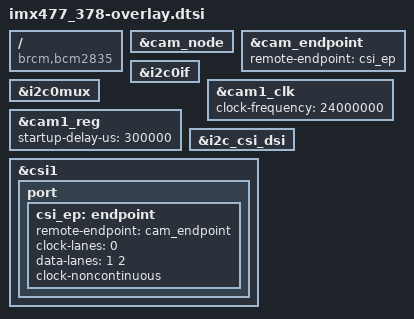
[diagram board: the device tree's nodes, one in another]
// SPDX-License-Identifier: GPL-2.0-only
// Definitions for IMX477 camera module on VC I2C bus

/{
	compatible = "brcm,bcm2835";

	fragment@0 {
		target = <&i2c0if>;
		__overlay__ {
			status = "okay";
		};
	};

	clk_frag: fragment@1 {
		target = <&cam1_clk>;
		cam_clk: __overlay__ {
			clock-frequency = <24000000>;
			status = "okay";
		};
	};

	fragment@2 {
		target = <&i2c0mux>;
		__overlay__ {
			status = "okay";
		};
	};

	reg_frag: fragment@3 {
		target = <&cam1_reg>;
		cam_reg: __overlay__ {
			startup-delay-us = <300000>;
		};
	};

	reg_alwayson_frag: fragment@99 {
		target = <&cam1_reg>;
		__dormant__ {
			regulator-always-on;
		};
	};

	i2c_frag: fragment@100 {
		target = <&i2c_csi_dsi>;
		__overlay__ {
			#address-cells = <1>;
			#size-cells = <0>;
			status = "okay";

			#include "imx477_378.dtsi"
		};
	};

	csi_frag: fragment@101 {
		target = <&csi1>;
		csi: __overlay__ {
			status = "okay";

			port {
				csi_ep: endpoint {
					remote-endpoint = <&cam_endpoint>;
					clock-lanes = <0>;
					data-lanes = <1 2>;
					clock-noncontinuous;
				};
			};
		};
	};

	fragment@102 {
		target = <&csi1>;
		__dormant__ {
			compatible = "brcm,bcm2835-unicam-legacy";
		};
	};

	__overrides__ {
		rotation = <&cam_node>,"rotation:0";
		orientation = <&cam_node>,"orientation:0";
		media-controller = <0>,"!102";
		cam0 = <&i2c_frag>, "target:0=",<&i2c_csi_dsi0>,
		       <&csi_frag>, "target:0=",<&csi0>,
		       <&clk_frag>, "target:0=",<&cam0_clk>,
		       <&reg_frag>, "target:0=",<&cam0_reg>,
		       <&reg_alwayson_frag>, "target:0=",<&cam0_reg>,
		       <&cam_node>, "clocks:0=",<&cam0_clk>,
		       <&cam_node>, "VANA-supply:0=",<&cam0_reg>;
		always-on = <0>, "+99";
	};
};

&cam_node {
	status = "okay";
};

&cam_endpoint {
	remote-endpoint = <&csi_ep>;
};
